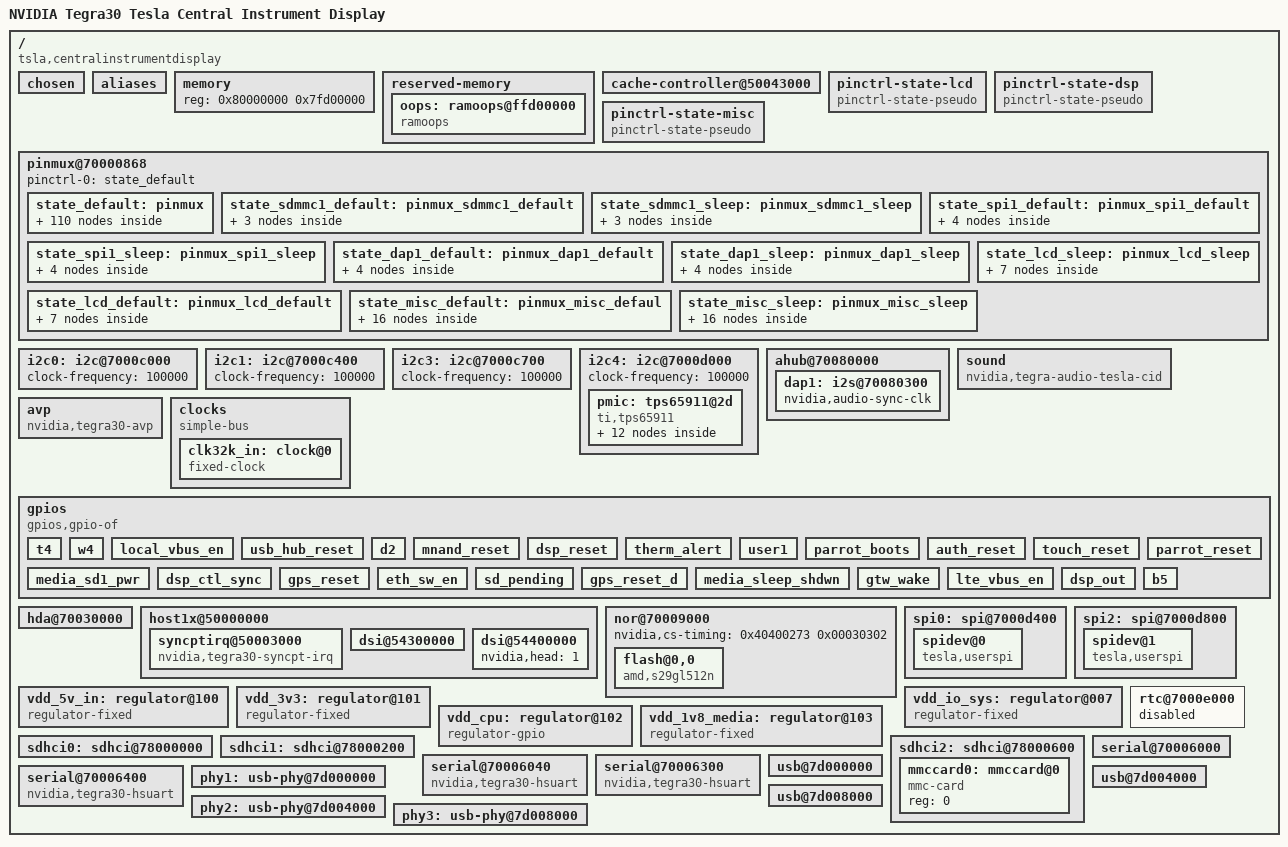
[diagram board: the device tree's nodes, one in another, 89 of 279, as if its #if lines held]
/dts-v1/;

#include "tegra30.dtsi"
#include "tegra30-platformdevice-compat.dtsi"

/ {
	model = "NVIDIA Tegra30 Tesla Central Instrument Display";
	compatible = "tsla,centralinstrumentdisplay", "nvidia,tegra30";

	chosen {
		/* for initial, just boot to a ram disc */
		bootargs = "console=ttyS0,115200n8 earlyprintk root=/dev/ram0";
	};

	aliases {
		serial0 = &uarta;
		serial1 = &uartb;
		serial2 = &uartc;
		serial3 = &uartd;
		serial4 = &uarte;
		i2c0 = &i2c0;
		i2c1 = &i2c1;
		i2c3 = &i2c3;
		i2c4 = &i2c4;
		spi0 = &spi0;
		spi2 = &spi2;
		mmc0 = &sdhci2;
		mmc1 = &sdhci0;
		mmc2 = &sdhci1;
		mmcblock0 = &mmccard0;
	};

	memory {
		/*
		 * Note, last 1 MiB is either reserved or unusable, and
		 * the 2 MiB below that is reserved for ramoops pstore.
		 */
		reg = <0x80000000 0x7fd00000>;
	};

	reserved-memory {
		#size-cells = <1>;
		#address-cells = <1>;
		ranges;

		oops: ramoops@ffd00000 {
			compatible = "ramoops";
			reg = <0xffd00000 0x200000>;
			record-size = <0x20000>;	/* 128KiB for oops */
			console-size = <0x2000>;	/* 8KiB */
			pmsg-size = <0x2000>;
			no-dump-oops;
			no-map;
		};
	};

	/* updated pl310 settings */
	cache-controller@50043000 {
		prefetch-data = <1>;
		prefetch-instr = <1>;
		arm,filter-ranges = < 0x80000000 0x7ff00000 >;
	};

	pinctrl-state-lcd {
		compatible = "pinctrl-state-pseudo";

		pinctrl-names = "default", "sleep";
		pinctrl-0 = <&state_lcd_default>;
		pinctrl-1 = <&state_lcd_sleep>;
	};

	pinctrl-state-dsp {
		compatible = "pinctrl-state-pseudo";

		pinctrl-names = "default", "sleep";
		pinctrl-0 = <&state_dap1_default &state_spi1_default>;
		pinctrl-1 = <&state_dap1_sleep &state_spi1_sleep>;
	};

	pinctrl-state-misc {
		compatible = "pinctrl-state-pseudo";

		pinctrl-names = "default", "sleep";
		pinctrl-0 = <&state_misc_default>;
		pinctrl-1 = <&state_misc_sleep>;
	};

	pinmux@70000868 {
		pinctrl-names = "default";
		pinctrl-0 = <&state_default>;

		state_default: pinmux {

			/* Pad Control Groups */
			ao1 {
				nvidia,pins = "drive_ao1";
				nvidia,high-speed-mode = <TEGRA_PIN_DISABLE>;
				nvidia,schmitt = <TEGRA_PIN_ENABLE>;
				nvidia,low-power-mode = <TEGRA_PIN_LP_DRIVE_DIV_1>;
				nvidia,pull-down-strength = <31>;
				nvidia,pull-up-strength = <31>;
				nvidia,slew-rate-rising = <TEGRA_PIN_SLEW_RATE_FASTEST>;
				nvidia,slew-rate-falling = <TEGRA_PIN_SLEW_RATE_FASTEST>;
			};
			at1 {
				nvidia,pins = "drive_at1";
				nvidia,high-speed-mode = <TEGRA_PIN_ENABLE>;
				nvidia,schmitt = <TEGRA_PIN_ENABLE>;
				nvidia,low-power-mode = <TEGRA_PIN_LP_DRIVE_DIV_8>;
				nvidia,pull-down-strength = <0>;
				nvidia,pull-up-strength = <0>;
				nvidia,slew-rate-rising = <TEGRA_PIN_SLEW_RATE_SLOWEST>;
				nvidia,slew-rate-falling = <TEGRA_PIN_SLEW_RATE_SLOWEST>;
			};
			at2 {
				nvidia,pins = "drive_at2";
				nvidia,high-speed-mode = <TEGRA_PIN_ENABLE>;
				nvidia,schmitt = <TEGRA_PIN_ENABLE>;
				nvidia,low-power-mode = <TEGRA_PIN_LP_DRIVE_DIV_8>;
				nvidia,pull-down-strength = <0>;
				nvidia,pull-up-strength = <0>;
				nvidia,slew-rate-rising = <TEGRA_PIN_SLEW_RATE_SLOWEST>;
				nvidia,slew-rate-falling = <TEGRA_PIN_SLEW_RATE_SLOWEST>;
			};
			at3 {
				nvidia,pins = "drive_at3";
				nvidia,high-speed-mode = <TEGRA_PIN_ENABLE>;
				nvidia,schmitt = <TEGRA_PIN_ENABLE>;
				nvidia,low-power-mode = <TEGRA_PIN_LP_DRIVE_DIV_8>;
				nvidia,pull-down-strength = <0>;
				nvidia,pull-up-strength = <0>;
				nvidia,slew-rate-rising = <TEGRA_PIN_SLEW_RATE_SLOWEST>;
				nvidia,slew-rate-falling = <TEGRA_PIN_SLEW_RATE_SLOWEST>;
			};
			at4 {
				nvidia,pins = "drive_at4";
				nvidia,high-speed-mode = <TEGRA_PIN_DISABLE>;
				nvidia,schmitt = <TEGRA_PIN_DISABLE>;
				nvidia,low-power-mode = <TEGRA_PIN_LP_DRIVE_DIV_1>;
				nvidia,pull-down-strength = <0>;
				nvidia,pull-up-strength = <0>;
				nvidia,slew-rate-rising = <TEGRA_PIN_SLEW_RATE_SLOWEST>;
				nvidia,slew-rate-falling = <TEGRA_PIN_SLEW_RATE_SLOWEST>;
			};
			at5 {
				nvidia,pins = "drive_at5";
				nvidia,high-speed-mode = <TEGRA_PIN_DISABLE>;
				nvidia,schmitt = <TEGRA_PIN_ENABLE>;
				nvidia,low-power-mode = <TEGRA_PIN_LP_DRIVE_DIV_1>;
				nvidia,pull-down-strength = <12>;
				nvidia,pull-up-strength = <30>;
				nvidia,slew-rate-rising = <TEGRA_PIN_SLEW_RATE_FASTEST>;
				nvidia,slew-rate-falling = <TEGRA_PIN_SLEW_RATE_FASTEST>;
			};
			dap1 {
				nvidia,pins = "drive_dap1";
				nvidia,high-speed-mode = <TEGRA_PIN_DISABLE>;
				nvidia,schmitt = <TEGRA_PIN_DISABLE>;
				nvidia,low-power-mode = <TEGRA_PIN_LP_DRIVE_DIV_1>;
				nvidia,pull-down-strength = <31>;
				nvidia,pull-up-strength = <31>;
				nvidia,slew-rate-rising = <TEGRA_PIN_SLEW_RATE_SLOWEST>;
				nvidia,slew-rate-falling = <TEGRA_PIN_SLEW_RATE_SLOWEST>;
			};
			dap2 {
				nvidia,pins = "drive_dap2";
				nvidia,high-speed-mode = <TEGRA_PIN_ENABLE>;
				nvidia,schmitt = <TEGRA_PIN_ENABLE>;
				nvidia,low-power-mode = <TEGRA_PIN_LP_DRIVE_DIV_8>;
				nvidia,pull-down-strength = <0>;
				nvidia,pull-up-strength = <0>;
				nvidia,slew-rate-rising = <TEGRA_PIN_SLEW_RATE_SLOWEST>;
				nvidia,slew-rate-falling = <TEGRA_PIN_SLEW_RATE_SLOWEST>;
			};
			dap3 {
				nvidia,pins = "drive_dap3";
				nvidia,high-speed-mode = <TEGRA_PIN_DISABLE>;
				nvidia,schmitt = <TEGRA_PIN_DISABLE>;
				nvidia,low-power-mode = <TEGRA_PIN_LP_DRIVE_DIV_1>;
				nvidia,pull-down-strength = <31>;
				nvidia,pull-up-strength = <31>;
				nvidia,slew-rate-rising = <TEGRA_PIN_SLEW_RATE_SLOWEST>;
				nvidia,slew-rate-falling = <TEGRA_PIN_SLEW_RATE_SLOWEST>;
			};
			dap4 {
				nvidia,pins = "drive_dap4";
				nvidia,high-speed-mode = <TEGRA_PIN_ENABLE>;
				nvidia,schmitt = <TEGRA_PIN_ENABLE>;
				nvidia,low-power-mode = <TEGRA_PIN_LP_DRIVE_DIV_8>;
				nvidia,pull-down-strength = <0>;
				nvidia,pull-up-strength = <0>;
				nvidia,slew-rate-rising = <TEGRA_PIN_SLEW_RATE_SLOWEST>;
				nvidia,slew-rate-falling = <TEGRA_PIN_SLEW_RATE_SLOWEST>;
			};
			dbg {
				nvidia,pins = "drive_dbg";
				nvidia,high-speed-mode = <TEGRA_PIN_ENABLE>;
				nvidia,schmitt = <TEGRA_PIN_ENABLE>;
				nvidia,low-power-mode = <TEGRA_PIN_LP_DRIVE_DIV_2>;
				nvidia,pull-down-strength = <20>;
				nvidia,pull-up-strength = <0>;
				nvidia,slew-rate-rising = <TEGRA_PIN_SLEW_RATE_SLOWEST>;
				nvidia,slew-rate-falling = <TEGRA_PIN_SLEW_RATE_SLOWEST>;
			};
			ddc {
				nvidia,pins = "drive_ddc";
				nvidia,high-speed-mode = <TEGRA_PIN_DISABLE>;
				nvidia,schmitt = <TEGRA_PIN_ENABLE>;
				nvidia,low-power-mode = <TEGRA_PIN_LP_DRIVE_DIV_1>;
				nvidia,pull-down-strength = <31>;
				nvidia,pull-up-strength = <31>;
				nvidia,slew-rate-rising = <TEGRA_PIN_SLEW_RATE_FASTEST>;
				nvidia,slew-rate-falling = <TEGRA_PIN_SLEW_RATE_FASTEST>;
			};
			gme {
				nvidia,pins = "drive_gme";
				nvidia,high-speed-mode = <TEGRA_PIN_DISABLE>;
				nvidia,schmitt = <TEGRA_PIN_ENABLE>;
				nvidia,low-power-mode = <TEGRA_PIN_LP_DRIVE_DIV_1>;
				nvidia,pull-down-strength = <1>;
				nvidia,pull-up-strength = <4>;
				nvidia,slew-rate-rising = <TEGRA_PIN_SLEW_RATE_SLOWEST>;
				nvidia,slew-rate-falling = <TEGRA_PIN_SLEW_RATE_SLOWEST>;
			};
			gmf {
				nvidia,pins = "drive_gmf";
				nvidia,high-speed-mode = <TEGRA_PIN_DISABLE>;
				nvidia,schmitt = <TEGRA_PIN_ENABLE>;
				nvidia,low-power-mode = <TEGRA_PIN_LP_DRIVE_DIV_1>;
				nvidia,pull-down-strength = <0>;
				nvidia,pull-up-strength = <0>;
				nvidia,slew-rate-rising = <TEGRA_PIN_SLEW_RATE_SLOWEST>;
				nvidia,slew-rate-falling = <TEGRA_PIN_SLEW_RATE_SLOWEST>;
			};
			gmg {
				nvidia,pins = "drive_gmg";
				nvidia,high-speed-mode = <TEGRA_PIN_DISABLE>;
				nvidia,schmitt = <TEGRA_PIN_ENABLE>;
				nvidia,low-power-mode = <TEGRA_PIN_LP_DRIVE_DIV_1>;
				nvidia,pull-down-strength = <3>;
				nvidia,pull-up-strength = <0>;
				nvidia,slew-rate-rising = <TEGRA_PIN_SLEW_RATE_SLOWEST>;
				nvidia,slew-rate-falling = <TEGRA_PIN_SLEW_RATE_SLOWEST>;
			};
			gmh {
				nvidia,pins = "drive_gmh";
				nvidia,high-speed-mode = <TEGRA_PIN_DISABLE>;
				nvidia,schmitt = <TEGRA_PIN_ENABLE>;
				nvidia,low-power-mode = <TEGRA_PIN_LP_DRIVE_DIV_1>;
				nvidia,pull-down-strength = <0>;
				nvidia,pull-up-strength = <12>;
				nvidia,slew-rate-rising = <TEGRA_PIN_SLEW_RATE_SLOWEST>;
				nvidia,slew-rate-falling = <TEGRA_PIN_SLEW_RATE_SLOWEST>;
			};
			lcd1 {
				nvidia,pins = "drive_lcd1";
				nvidia,high-speed-mode = <TEGRA_PIN_DISABLE>;
				nvidia,schmitt = <TEGRA_PIN_ENABLE>;
				nvidia,low-power-mode = <TEGRA_PIN_LP_DRIVE_DIV_1>;
				nvidia,pull-down-strength = <31>;
				nvidia,pull-up-strength = <31>;
				nvidia,slew-rate-rising = <TEGRA_PIN_SLEW_RATE_FASTEST>;
				nvidia,slew-rate-falling = <TEGRA_PIN_SLEW_RATE_FASTEST>;
			};
			lcd2 {
				nvidia,pins = "drive_lcd2";
				nvidia,high-speed-mode = <TEGRA_PIN_DISABLE>;
				nvidia,schmitt = <TEGRA_PIN_ENABLE>;
				nvidia,low-power-mode = <TEGRA_PIN_LP_DRIVE_DIV_1>;
				nvidia,pull-down-strength = <6>;
				nvidia,pull-up-strength = <6>;
				nvidia,slew-rate-rising = <TEGRA_PIN_SLEW_RATE_FASTEST>;
				nvidia,slew-rate-falling = <TEGRA_PIN_SLEW_RATE_FASTEST>;
			};
			spi {
				nvidia,pins = "drive_spi";
				nvidia,high-speed-mode = <TEGRA_PIN_ENABLE>;
				nvidia,schmitt = <TEGRA_PIN_ENABLE>;
				nvidia,low-power-mode = <TEGRA_PIN_LP_DRIVE_DIV_8>;
				nvidia,pull-down-strength = <0>;
				nvidia,pull-up-strength = <0>;
				nvidia,slew-rate-rising = <TEGRA_PIN_SLEW_RATE_SLOWEST>;
				nvidia,slew-rate-falling = <TEGRA_PIN_SLEW_RATE_SLOWEST>;
			};
			uaa {
				nvidia,pins = "drive_uaa";
				nvidia,high-speed-mode = <TEGRA_PIN_DISABLE>;
				nvidia,schmitt = <TEGRA_PIN_DISABLE>;
				nvidia,low-power-mode = <TEGRA_PIN_LP_DRIVE_DIV_1>;
				nvidia,pull-down-strength = <0>;
				nvidia,pull-up-strength = <0>;
				nvidia,slew-rate-rising = <TEGRA_PIN_SLEW_RATE_SLOWEST>;
				nvidia,slew-rate-falling = <TEGRA_PIN_SLEW_RATE_SLOWEST>;
			};
			uab {
				nvidia,pins = "drive_uab";
				nvidia,high-speed-mode = <TEGRA_PIN_DISABLE>;
				nvidia,schmitt = <TEGRA_PIN_ENABLE>;
				nvidia,low-power-mode = <TEGRA_PIN_LP_DRIVE_DIV_1>;
				nvidia,pull-down-strength = <4>;
				nvidia,pull-up-strength = <1>;
				nvidia,slew-rate-rising = <TEGRA_PIN_SLEW_RATE_SLOWEST>;
				nvidia,slew-rate-falling = <TEGRA_PIN_SLEW_RATE_SLOWEST>;
			};
			uda {
				nvidia,pins = "drive_uda";
				nvidia,high-speed-mode = <TEGRA_PIN_DISABLE>;
				nvidia,schmitt = <TEGRA_PIN_ENABLE>;
				nvidia,low-power-mode = <TEGRA_PIN_LP_DRIVE_DIV_1>;
				nvidia,pull-down-strength = <4>;
				nvidia,pull-up-strength = <1>;
				nvidia,slew-rate-rising = <TEGRA_PIN_SLEW_RATE_SLOWEST>;
				nvidia,slew-rate-falling = <TEGRA_PIN_SLEW_RATE_SLOWEST>;
			};
			uart2 {
				nvidia,pins = "drive_uart2";
				nvidia,high-speed-mode = <TEGRA_PIN_ENABLE>;
				nvidia,schmitt = <TEGRA_PIN_ENABLE>;
				nvidia,low-power-mode = <TEGRA_PIN_LP_DRIVE_DIV_8>;
				nvidia,pull-down-strength = <0>;
				nvidia,pull-up-strength = <0>;
				nvidia,slew-rate-rising = <TEGRA_PIN_SLEW_RATE_SLOWEST>;
				nvidia,slew-rate-falling = <TEGRA_PIN_SLEW_RATE_SLOWEST>;
			};
			uart3 {
				nvidia,pins = "drive_uart3";
				nvidia,high-speed-mode = <TEGRA_PIN_ENABLE>;
				nvidia,schmitt = <TEGRA_PIN_ENABLE>;
				nvidia,low-power-mode = <TEGRA_PIN_LP_DRIVE_DIV_8>;
				nvidia,pull-down-strength = <0>;
				nvidia,pull-up-strength = <0>;
				nvidia,slew-rate-rising = <TEGRA_PIN_SLEW_RATE_SLOWEST>;
				nvidia,slew-rate-falling = <TEGRA_PIN_SLEW_RATE_SLOWEST>;
			};
			sdio1 {
				nvidia,pins = "drive_sdio1";
				nvidia,high-speed-mode = <TEGRA_PIN_DISABLE>;
				nvidia,schmitt = <TEGRA_PIN_DISABLE>;
				nvidia,pull-down-strength = <29>;
				nvidia,pull-up-strength = <22>;
				nvidia,slew-rate-rising = <TEGRA_PIN_SLEW_RATE_SLOWEST>;
				nvidia,slew-rate-falling = <TEGRA_PIN_SLEW_RATE_SLOWEST>;
			};
			sdio3 {
				nvidia,pins = "drive_sdio3";
				nvidia,high-speed-mode = <TEGRA_PIN_DISABLE>;
				nvidia,schmitt = <TEGRA_PIN_ENABLE>;
				nvidia,pull-down-strength = <4>;
				nvidia,pull-up-strength = <1>;
				nvidia,slew-rate-rising = <TEGRA_PIN_SLEW_RATE_FASTEST>;
				nvidia,slew-rate-falling = <TEGRA_PIN_SLEW_RATE_FASTEST>;
			};

			/* CRT pinmux */
			crt_hsync_pv6 {
				nvidia,pins = "crt_hsync_pv6";
				nvidia,function = "crt";
				nvidia,pull = <TEGRA_PIN_PULL_NONE>;
				nvidia,tristate = <TEGRA_PIN_DISABLE>;
				nvidia,enable-input = <TEGRA_PIN_ENABLE>;
			};

			crt_vsync_pv7 {
				nvidia,pins = "crt_vsync_pv7";
				nvidia,function = "rsvd2";
				nvidia,pull = <TEGRA_PIN_PULL_NONE>;
				nvidia,tristate = <TEGRA_PIN_DISABLE>;
				nvidia,enable-input = <TEGRA_PIN_ENABLE>;
			};


			/* SDMMC2 pinmux */
			kb_row10_ps2 {
				nvidia,pins = "kb_row10_ps2";
				nvidia,function = "sdmmc2";
				nvidia,pull = <TEGRA_PIN_PULL_NONE>;
				nvidia,tristate = <TEGRA_PIN_DISABLE>;
				nvidia,enable-input = <TEGRA_PIN_ENABLE>;
			};
			kb_rows {
				nvidia,pins = "kb_row11_ps3",
						"kb_row12_ps4",
						"kb_row13_ps5",
						"kb_row14_ps6",
						"kb_row15_ps7",
						"kb_row6_pr6",
						"kb_row7_pr7",
						"kb_row8_ps0",
						"kb_row9_ps1";
				nvidia,function = "sdmmc2";
				nvidia,pull = <TEGRA_PIN_PULL_UP>;
				nvidia,tristate = <TEGRA_PIN_DISABLE>;
				nvidia,enable-input = <TEGRA_PIN_ENABLE>;
			};

			/* SDMMC3 pinmux*/
			sdmmc3_cmd_pa7 {
				nvidia,pins = "sdmmc3_cmd_pa7";
				nvidia,function = "sdmmc3";
				nvidia,pull = <TEGRA_PIN_PULL_NONE>;
				nvidia,tristate = <TEGRA_PIN_DISABLE>;
				nvidia,enable-input = <TEGRA_PIN_ENABLE>;
			};

			sdmmc3_dat3_pb4 {
				nvidia,pins = "sdmmc3_dat3_pb4";
				nvidia,function = "rsvd1";
				nvidia,pull = <TEGRA_PIN_PULL_NONE>;
				nvidia,tristate = <TEGRA_PIN_DISABLE>;
				nvidia,enable-input = <TEGRA_PIN_ENABLE>;
			};

			sdmmc3_dat7_pd4 {
				nvidia,pins = "sdmmc3_dat7_pd4";
				nvidia,function = "sdmmc3";
				nvidia,pull = <TEGRA_PIN_PULL_NONE>;
				nvidia,tristate = <TEGRA_PIN_DISABLE>;
				nvidia,enable-input = <TEGRA_PIN_ENABLE>;
			};


			/* SDMMC4 pinmux */
			cam_i2c_scl_pbb1 {
				nvidia,pins = "cam_i2c_scl_pbb1";
				nvidia,function = "sdmmc4";
				nvidia,pull = <TEGRA_PIN_PULL_UP>;
				nvidia,tristate = <TEGRA_PIN_DISABLE>;
				nvidia,enable-input = <TEGRA_PIN_ENABLE>;
				nvidia,open-drain = <TEGRA_PIN_DISABLE>;
				nvidia,io-reset = <TEGRA_PIN_DISABLE>;
			};
			cam_i2c_sda_pbb2 {
				nvidia,pins = "cam_i2c_sda_pbb2";
				nvidia,function = "sdmmc4";
				nvidia,pull = <TEGRA_PIN_PULL_UP>;
				nvidia,tristate = <TEGRA_PIN_DISABLE>;
				nvidia,enable-input = <TEGRA_PIN_ENABLE>;
				nvidia,open-drain = <TEGRA_PIN_DISABLE>;
				nvidia,io-reset = <TEGRA_PIN_DISABLE>;
			};
			cam_mclk_pcc0 {
				nvidia,pins = "cam_mclk_pcc0";
				nvidia,function = "sdmmc4";
				nvidia,pull = <TEGRA_PIN_PULL_NONE>;
				nvidia,tristate = <TEGRA_PIN_DISABLE>;
				nvidia,enable-input = <TEGRA_PIN_ENABLE>;
			};
			pcc1 {
				nvidia,pins = "pcc1";
				nvidia,function = "sdmmc4";
				nvidia,pull = <TEGRA_PIN_PULL_NONE>;
				nvidia,tristate = <TEGRA_PIN_DISABLE>;
				nvidia,enable-input = <TEGRA_PIN_ENABLE>;
			};
			pcc2 {
				nvidia,pins = "pcc2";
				nvidia,function = "rsvd4";
				nvidia,pull = <TEGRA_PIN_PULL_UP>;
				nvidia,tristate = <TEGRA_PIN_DISABLE>;
				nvidia,enable-input = <TEGRA_PIN_ENABLE>;
			};
			pbb0 {
				nvidia,pins = "pbb0";
				nvidia,function = "sdmmc4";
				nvidia,pull = <TEGRA_PIN_PULL_UP>;
				nvidia,tristate = <TEGRA_PIN_DISABLE>;
				nvidia,enable-input = <TEGRA_PIN_ENABLE>;
			};
			pbb3 {
				nvidia,pins = "pbb3";
				nvidia,function = "sdmmc4";
				nvidia,pull = <TEGRA_PIN_PULL_UP>;
				nvidia,tristate = <TEGRA_PIN_DISABLE>;
				nvidia,enable-input = <TEGRA_PIN_ENABLE>;
			};
			pbb4 {
				nvidia,pins = "pbb4";
				nvidia,function = "sdmmc4";
				nvidia,pull = <TEGRA_PIN_PULL_UP>;
				nvidia,tristate = <TEGRA_PIN_DISABLE>;
				nvidia,enable-input = <TEGRA_PIN_ENABLE>;
			};
			pbb5 {
				nvidia,pins = "pbb5";
				nvidia,function = "sdmmc4";
				nvidia,pull = <TEGRA_PIN_PULL_UP>;
				nvidia,tristate = <TEGRA_PIN_DISABLE>;
				nvidia,enable-input = <TEGRA_PIN_ENABLE>;
			};
			pbb6 {
				nvidia,pins = "pbb6";
				nvidia,function = "sdmmc4";
				nvidia,pull = <TEGRA_PIN_PULL_UP>;
				nvidia,tristate = <TEGRA_PIN_DISABLE>;
				nvidia,enable-input = <TEGRA_PIN_ENABLE>;
			};
			pbb7 {
				nvidia,pins = "pbb7";
				nvidia,function = "sdmmc4";
				nvidia,pull = <TEGRA_PIN_PULL_UP>;
				nvidia,tristate = <TEGRA_PIN_DISABLE>;
				nvidia,enable-input = <TEGRA_PIN_ENABLE>;
			};

			/* UART1 pinmux */
			ulpi_data0_po1 {
				nvidia,pins = "ulpi_data0_po1";
				nvidia,function = "uarta";
				nvidia,pull = <TEGRA_PIN_PULL_NONE>;
				nvidia,tristate = <TEGRA_PIN_DISABLE>;
				nvidia,enable-input = <TEGRA_PIN_DISABLE>;
			};
			/* I2C1 pinmux */
			gen1_i2c_scl_pc4 {
				nvidia,pins = "gen1_i2c_scl_pc4";
				nvidia,function = "i2c1";
				nvidia,pull = <TEGRA_PIN_PULL_NONE>;
				nvidia,tristate = <TEGRA_PIN_DISABLE>;
				nvidia,enable-input = <TEGRA_PIN_ENABLE>;
				nvidia,lock = <TEGRA_PIN_DISABLE>;
				nvidia,open-drain = <TEGRA_PIN_ENABLE>;
			};
			gen1_i2c_sda_pc5 {
				nvidia,pins = "gen1_i2c_sda_pc5";
				nvidia,function = "i2c1";
				nvidia,pull = <TEGRA_PIN_PULL_NONE>;
				nvidia,tristate = <TEGRA_PIN_DISABLE>;
				nvidia,enable-input = <TEGRA_PIN_ENABLE>;
				nvidia,lock = <TEGRA_PIN_DISABLE>;
				nvidia,open-drain = <TEGRA_PIN_ENABLE>;
			};

			/* I2C2 pinmux */
			gen2_i2c_scl_pt5 {
				nvidia,pins = "gen2_i2c_scl_pt5";
				nvidia,function = "i2c2";
				nvidia,pull = <TEGRA_PIN_PULL_NONE>;
				nvidia,tristate = <TEGRA_PIN_DISABLE>;
				nvidia,enable-input = <TEGRA_PIN_ENABLE>;
				nvidia,lock = <TEGRA_PIN_DISABLE>;
				nvidia,open-drain = <TEGRA_PIN_ENABLE>;
			};
			gen2_i2c_sda_pt6 {
				nvidia,pins = "gen2_i2c_sda_pt6";
				nvidia,function = "i2c2";
				nvidia,pull = <TEGRA_PIN_PULL_NONE>;
				nvidia,tristate = <TEGRA_PIN_DISABLE>;
				nvidia,enable-input = <TEGRA_PIN_ENABLE>;
				nvidia,lock = <TEGRA_PIN_DISABLE>;
				nvidia,open-drain = <TEGRA_PIN_ENABLE>;
			};

			/* I2C4 pinmux */
			ddc_scl_pv4 {
				nvidia,pins = "ddc_scl_pv4";
				nvidia,function = "i2c4";
				nvidia,pull = <TEGRA_PIN_PULL_NONE>;
				nvidia,tristate = <TEGRA_PIN_DISABLE>;
				nvidia,lock = <TEGRA_PIN_DISABLE>;
				nvidia,enable-input = <TEGRA_PIN_ENABLE>;
			};
			ddc_sda_pv5 {
				nvidia,pins = "ddc_sda_pv5";
				nvidia,function = "i2c4";
				nvidia,pull = <TEGRA_PIN_PULL_NONE>;
				nvidia,tristate = <TEGRA_PIN_DISABLE>;
				nvidia,lock = <TEGRA_PIN_DISABLE>;
				nvidia,enable-input = <TEGRA_PIN_ENABLE>;
			};

			/* PWRI2C pinmux */
			pwr_i2c_scl_pz6 {
				nvidia,pins = "pwr_i2c_scl_pz6";
				nvidia,function = "i2cpwr";
				nvidia,pull = <TEGRA_PIN_PULL_NONE>;
				nvidia,tristate = <TEGRA_PIN_DISABLE>;
				nvidia,enable-input = <TEGRA_PIN_ENABLE>;
				nvidia,open-drain = <TEGRA_PIN_ENABLE>;
			};
			pwr_i2c_sda_pz7 {
				nvidia,pins = "pwr_i2c_sda_pz7";
				nvidia,function = "i2cpwr";
				nvidia,pull = <TEGRA_PIN_PULL_NONE>;
				nvidia,tristate = <TEGRA_PIN_DISABLE>;
				nvidia,enable-input = <TEGRA_PIN_ENABLE>;
				nvidia,open-drain = <TEGRA_PIN_ENABLE>;
			};


			/* SPI2 pinmux*/
			spi1_cs0_n_px6 {
				nvidia,pins = "spi1_cs0_n_px6";
				nvidia,function = "spi2";
				nvidia,pull = <TEGRA_PIN_PULL_NONE>;
				nvidia,tristate = <TEGRA_PIN_DISABLE>;
				nvidia,enable-input = <TEGRA_PIN_ENABLE>;
			};
			spi1_sck_px5 {
				nvidia,pins = "spi1_sck_px5";
				nvidia,function = "spi2";
				nvidia,pull = <TEGRA_PIN_PULL_NONE>;
				nvidia,tristate = <TEGRA_PIN_DISABLE>;
				nvidia,enable-input = <TEGRA_PIN_ENABLE>;
			};
			spi2_cs1_n_pw2 {
				nvidia,pins = "spi2_cs1_n_pw2";
				nvidia,function = "spi2";
				nvidia,pull = <TEGRA_PIN_PULL_NONE>;
				nvidia,tristate = <TEGRA_PIN_ENABLE>;
				nvidia,enable-input = <TEGRA_PIN_ENABLE>;
			};
			spi2_cs2_n_pw3 {
				nvidia,pins = "spi2_cs2_n_pw3";
				nvidia,function = "spi2";
				nvidia,pull = <TEGRA_PIN_PULL_NONE>;
				nvidia,tristate = <TEGRA_PIN_DISABLE>;
				nvidia,enable-input = <TEGRA_PIN_ENABLE>;
			};
			ulpi_data4_po5 {
				nvidia,pins = "ulpi_data4_po5";
				nvidia,function = "spi2";
				nvidia,pull = <TEGRA_PIN_PULL_NONE>;
				nvidia,tristate = <TEGRA_PIN_DISABLE>;
				nvidia,enable-input = <TEGRA_PIN_ENABLE>;
			};
			ulpi_data5_po6 {
				nvidia,pins = "ulpi_data5_po6";
				nvidia,function = "spi2";
				nvidia,pull = <TEGRA_PIN_PULL_NONE>;
				nvidia,tristate = <TEGRA_PIN_DISABLE>;
				nvidia,enable-input = <TEGRA_PIN_ENABLE>;
			};
			ulpi_data6_po7 {
				nvidia,pins = "ulpi_data6_po7";
				nvidia,function = "spi2";
				nvidia,pull = <TEGRA_PIN_PULL_NONE>;
				nvidia,tristate = <TEGRA_PIN_DISABLE>;
				nvidia,enable-input = <TEGRA_PIN_ENABLE>;
			};
			ulpi_data7_po0 {
				nvidia,pins = "ulpi_data7_po0";
				nvidia,function = "spi2";
				nvidia,pull = <TEGRA_PIN_PULL_NONE>;
				nvidia,tristate = <TEGRA_PIN_DISABLE>;
				nvidia,enable-input = <TEGRA_PIN_ENABLE>;
			};

			/* SPDIF pinmux */
			spdif_in_pk6 {
				nvidia,pins = "spdif_in_pk6";
				nvidia,function = "spdif";
				nvidia,pull = <TEGRA_PIN_PULL_NONE>;
				nvidia,tristate = <TEGRA_PIN_ENABLE>;
				nvidia,enable-input = <TEGRA_PIN_ENABLE>;
			};

			/* DAP2 pinmux */
			dap3_fs_pp0 {
				nvidia,pins = "dap3_fs_pp0";
				nvidia,function = "i2s2";
				nvidia,pull = <TEGRA_PIN_PULL_NONE>;
				nvidia,tristate = <TEGRA_PIN_ENABLE>;
				nvidia,enable-input = <TEGRA_PIN_ENABLE>;
			};
			dap3_din_pp1 {
				nvidia,pins = "dap3_din_pp1";
				nvidia,function = "i2s2";
				nvidia,pull = <TEGRA_PIN_PULL_NONE>;
				nvidia,tristate = <TEGRA_PIN_ENABLE>;
				nvidia,enable-input = <TEGRA_PIN_ENABLE>;
			};
			dap3_dout_pp2 {
				nvidia,pins = "dap3_dout_pp2";
				nvidia,function = "i2s2";
				nvidia,pull = <TEGRA_PIN_PULL_NONE>;
				nvidia,tristate = <TEGRA_PIN_ENABLE>;
				nvidia,enable-input = <TEGRA_PIN_ENABLE>;
			};
			dap3_sclk_pp3 {
				nvidia,pins = "dap3_sclk_pp3";
				nvidia,function = "i2s2";
				nvidia,pull = <TEGRA_PIN_PULL_NONE>;
				nvidia,tristate = <TEGRA_PIN_ENABLE>;
				nvidia,enable-input = <TEGRA_PIN_ENABLE>;
			};

			/* DAP3 pinmux */
			sdmmc4_dat4_paa4 {
				nvidia,pins = "sdmmc4_dat4_paa4";
				nvidia,function = "i2s4";
				nvidia,pull = <TEGRA_PIN_PULL_NONE>;
				nvidia,tristate = <TEGRA_PIN_DISABLE>;
				nvidia,enable-input = <TEGRA_PIN_ENABLE>;
				nvidia,lock = <TEGRA_PIN_DISABLE>;
				nvidia,io-reset = <TEGRA_PIN_DISABLE>;
			};
			sdmmc4_dat5_paa5 {
				nvidia,pins = "sdmmc4_dat5_paa5";
				nvidia,function = "i2s4";
				nvidia,pull = <TEGRA_PIN_PULL_NONE>;
				nvidia,tristate = <TEGRA_PIN_DISABLE>;
				nvidia,enable-input = <TEGRA_PIN_ENABLE>;
				nvidia,lock = <TEGRA_PIN_DISABLE>;
				nvidia,io-reset = <TEGRA_PIN_DISABLE>;
			};
			sdmmc4_dat6_paa6 {
				nvidia,pins = "sdmmc4_dat6_paa6";
				nvidia,function = "i2s4";
				nvidia,pull = <TEGRA_PIN_PULL_NONE>;
				nvidia,tristate = <TEGRA_PIN_DISABLE>;
				nvidia,enable-input = <TEGRA_PIN_ENABLE>;
				nvidia,lock = <TEGRA_PIN_DISABLE>;
				nvidia,io-reset = <TEGRA_PIN_DISABLE>;
			};
			sdmmc4_dat7_paa7 {
				nvidia,pins = "sdmmc4_dat7_paa7";
				nvidia,function = "i2s4";
				nvidia,pull = <TEGRA_PIN_PULL_NONE>;
				nvidia,tristate = <TEGRA_PIN_DISABLE>;
				nvidia,enable-input = <TEGRA_PIN_ENABLE>;
				nvidia,lock = <TEGRA_PIN_DISABLE>;
				nvidia,io-reset = <TEGRA_PIN_DISABLE>;
			};

			/* NOR pinmux */
			gmi_input {
				nvidia,pins = "gmi_ad0_pg0",
						"gmi_ad1_pg1",
						"gmi_ad2_pg2",
						"gmi_ad3_pg3",
						"gmi_ad4_pg4",
						"gmi_ad5_pg5",
						"gmi_ad6_pg6",
						"gmi_ad7_pg7",
						"gmi_ad8_ph0",
						"gmi_ad9_ph1",
						"gmi_ad10_ph2",
						"gmi_ad11_ph3",
						"gmi_ad12_ph4",
						"gmi_ad13_ph5",
						"gmi_ad14_ph6",
						"gmi_ad15_ph7",
                        "gmi_wait_pi7";
				nvidia,function = "gmi";
				nvidia,pull = <TEGRA_PIN_PULL_NONE>;
				nvidia,tristate = <TEGRA_PIN_DISABLE>;
				nvidia,enable-input = <TEGRA_PIN_ENABLE>;
			};
			gmi_adv_n_pk0 {
				nvidia,pins = "gmi_adv_n_pk0";
				nvidia,function = "nand";
				nvidia,pull = <TEGRA_PIN_PULL_NONE>;
				nvidia,tristate = <TEGRA_PIN_DISABLE>;
				nvidia,enable-input = <TEGRA_PIN_DISABLE>;
			};
			gmi_clk_pk1 {
				nvidia,pins = "gmi_clk_pk1";
				nvidia,function = "nand";
				nvidia,pull = <TEGRA_PIN_PULL_NONE>;
				nvidia,tristate = <TEGRA_PIN_DISABLE>;
				nvidia,enable-input = <TEGRA_PIN_DISABLE>;
			};
			gmi_cs0_n_pj0 {
				nvidia,pins = "gmi_cs0_n_pj0";
				nvidia,function = "gmi";
				nvidia,pull = <TEGRA_PIN_PULL_NONE>;
				nvidia,tristate = <TEGRA_PIN_DISABLE>;
				nvidia,enable-input = <TEGRA_PIN_DISABLE>;
			};
			gmi_oe_n_pi1 {
				nvidia,pins = "gmi_oe_n_pi1";
				nvidia,function = "gmi";
				nvidia,pull = <TEGRA_PIN_PULL_NONE>;
				nvidia,tristate = <TEGRA_PIN_DISABLE>;
				nvidia,enable-input = <TEGRA_PIN_DISABLE>;
			};
			gmi_rst_n_pi4 {
				nvidia,pins = "gmi_rst_n_pi4";
				nvidia,function = "gmi";
				nvidia,pull = <TEGRA_PIN_PULL_UP>;
				nvidia,tristate = <TEGRA_PIN_ENABLE>;
				nvidia,enable-input = <TEGRA_PIN_DISABLE>;
			};
			gmi_out {
				nvidia,pins = "gmi_wp_n_pc7",
						"gmi_wr_n_pi0",
						"dap2_fs_pa2",
						"dap2_sclk_pa3",
						"dap2_din_pa4",
						"dap2_dout_pa5",
						"spi1_mosi_px4",
						"spi2_mosi_px0",
						"spi2_miso_px1",
						"spi2_sck_px2",
						"spi2_cs0_n_px3",
						"dap4_fs_pp4",
						"dap4_din_pp5",
						"dap4_dout_pp6",
						"dap4_sclk_pp7",
						"pu0",
						"pu1",
						"pu2",
						"pu3",
						"pu4",
						"pu5",
						"pu6",
						"uart2_cts_n_pj5",
						"uart2_rts_n_pj6",
						"uart3_cts_n_pa1",
						"uart3_rts_n_pc0",
						"uart3_txd_pw6",
						"uart3_rxd_pw7";
				nvidia,function = "gmi";
				nvidia,pull = <TEGRA_PIN_PULL_NONE>;
				nvidia,tristate = <TEGRA_PIN_DISABLE>;
				nvidia,enable-input = <TEGRA_PIN_DISABLE>;
			};

			/* DISPLAY pinmux*/
			lcd_pwr1_pc1 {
				nvidia,pins = "lcd_pwr1_pc1";
				nvidia,function = "displaya";
				nvidia,pull = <TEGRA_PIN_PULL_NONE>;
				nvidia,tristate = <TEGRA_PIN_DISABLE>;
				nvidia,enable-input = <TEGRA_PIN_ENABLE>;
			};
			lcd_pwr2_pc6 {
				nvidia,pins = "lcd_pwr2_pc6";
				nvidia,function = "displaya";
				nvidia,pull = <TEGRA_PIN_PULL_NONE>;
				nvidia,tristate = <TEGRA_PIN_DISABLE>;
				nvidia,enable-input = <TEGRA_PIN_ENABLE>;
			};
			lcd_cs0_n_pn4 {
				nvidia,pins = "lcd_cs0_n_pn4";
				nvidia,function = "rsvd4";
				nvidia,pull = <TEGRA_PIN_PULL_NONE>;
				nvidia,tristate = <TEGRA_PIN_DISABLE>;
				nvidia,enable-input = <TEGRA_PIN_ENABLE>;
			};

			/* PEX pinmux */
			pex_l1_prsnt_n_pdd4 {
				nvidia,pins = "pex_l1_prsnt_n_pdd4";
				nvidia,function = "pcie";
				nvidia,pull = <TEGRA_PIN_PULL_NONE>;
				nvidia,tristate = <TEGRA_PIN_ENABLE>;
				nvidia,enable-input = <TEGRA_PIN_ENABLE>;
			};
			pex_l1_rst_n_pdd5 {
				nvidia,pins = "pex_l1_rst_n_pdd5";
				nvidia,function = "pcie";
				nvidia,pull = <TEGRA_PIN_PULL_NONE>;
				nvidia,tristate = <TEGRA_PIN_ENABLE>;
				nvidia,enable-input = <TEGRA_PIN_DISABLE>;
			};
			pex_l1_clkreq_n_pdd6 {
				nvidia,pins = "pex_l1_clkreq_n_pdd6";
				nvidia,function = "pcie";
				nvidia,pull = <TEGRA_PIN_PULL_NONE>;
				nvidia,tristate = <TEGRA_PIN_DISABLE>;
				nvidia,enable-input = <TEGRA_PIN_ENABLE>;
			};
			pex_l2_prsnt_n_pdd7 {
				nvidia,pins = "pex_l2_prsnt_n_pdd7";
				nvidia,function = "pcie";
				nvidia,pull = <TEGRA_PIN_PULL_NONE>;
				nvidia,tristate = <TEGRA_PIN_ENABLE>;
				nvidia,enable-input = <TEGRA_PIN_ENABLE>;
			};
			pex_l2_rst_n_pcc6 {
				nvidia,pins = "pex_l2_rst_n_pcc6";
				nvidia,function = "pcie";
				nvidia,pull = <TEGRA_PIN_PULL_NONE>;
				nvidia,tristate = <TEGRA_PIN_ENABLE>;
				nvidia,enable-input = <TEGRA_PIN_DISABLE>;
			};
			pex_l2_clkreq_n_pcc7 {
				nvidia,pins = "pex_l2_clkreq_n_pcc7";
				nvidia,function = "pcie";
				nvidia,pull = <TEGRA_PIN_PULL_NONE>;
				nvidia,tristate = <TEGRA_PIN_DISABLE>;
				nvidia,enable-input = <TEGRA_PIN_ENABLE>;
			};

			/* CLK1_OUT pinmux*/
			clk1_out_pw4 {
				nvidia,pins = "clk1_out_pw4";
				nvidia,function = "extperiph1";
				nvidia,pull = <TEGRA_PIN_PULL_NONE>;
				nvidia,tristate = <TEGRA_PIN_DISABLE>;
				nvidia,enable-input = <TEGRA_PIN_ENABLE>;
			};

			/* VI pinmux */
			vi_input {
				nvidia,pins = "vi_d2_pl0",
						"vi_d3_pl1",
						"vi_d4_pl2",
						"vi_d5_pl3",
						"vi_d6_pl4",
						"vi_d7_pl5",
						"vi_d8_pl6",
						"vi_d9_pl7";
				nvidia,function = "vi";
				nvidia,pull = <TEGRA_PIN_PULL_NONE>;
				nvidia,tristate = <TEGRA_PIN_DISABLE>;
				nvidia,enable-input = <TEGRA_PIN_ENABLE>;
				nvidia,lock = <TEGRA_PIN_DISABLE>;
				nvidia,io-reset = <TEGRA_PIN_DISABLE>;
			};
			vi_pclk_pt0 {
				nvidia,pins = "vi_pclk_pt0";
				nvidia,function = "vi";
				nvidia,pull = <TEGRA_PIN_PULL_UP>;
				nvidia,tristate = <TEGRA_PIN_ENABLE>;
				nvidia,enable-input = <TEGRA_PIN_ENABLE>;
				nvidia,lock = <TEGRA_PIN_DISABLE>;
				nvidia,io-reset = <TEGRA_PIN_DISABLE>;
			};

			/* GPIO pinmux */
			vi_d0_pt4 {
				nvidia,pins = "vi_d0_pt4";
				nvidia,function = "rsvd2";
				nvidia,pull = <TEGRA_PIN_PULL_NONE>;
				nvidia,tristate = <TEGRA_PIN_DISABLE>;
				nvidia,enable-input = <TEGRA_PIN_ENABLE>;
			};

			clk1_req_pee2 {
				nvidia,pins = "clk1_req_pee2";
				nvidia,function = "rsvd3";
				nvidia,pull = <TEGRA_PIN_PULL_NONE>;
				nvidia,tristate = <TEGRA_PIN_DISABLE>;
				nvidia,enable-input = <TEGRA_PIN_ENABLE>;
			};
			clk2_req_pcc5 {
				nvidia,pins = "clk2_req_pcc5";
				nvidia,function = "rsvd3";
				nvidia,pull = <TEGRA_PIN_PULL_NONE>;
				nvidia,tristate = <TEGRA_PIN_DISABLE>;
				nvidia,enable-input = <TEGRA_PIN_DISABLE>;
			};
			lcd_sck_pz4 {
				nvidia,pins = "lcd_sck_pz4";
				nvidia,function = "spi5";
				nvidia,pull = <TEGRA_PIN_PULL_NONE>;
				nvidia,tristate = <TEGRA_PIN_DISABLE>;
				nvidia,enable-input = <TEGRA_PIN_ENABLE>;
			};
			clk3_out_pee0 {
				nvidia,pins = "clk3_out_pee0";
				nvidia,function = "extperiph3";
				nvidia,pull = <TEGRA_PIN_PULL_NONE>;
				nvidia,tristate = <TEGRA_PIN_DISABLE>;
				nvidia,enable-input = <TEGRA_PIN_ENABLE>;
			};
			hdmi_int_pn7 {
				nvidia,pins = "hdmi_int_pn7";
				nvidia,function = "hdmi";
				nvidia,pull = <TEGRA_PIN_PULL_NONE>;
				nvidia,tristate = <TEGRA_PIN_ENABLE>;
				nvidia,enable-input = <TEGRA_PIN_ENABLE>;
			};
			lcd_dc0_pn6 {
				nvidia,pins = "lcd_dc0_pn6";
				nvidia,function = "rsvd3";
				nvidia,pull = <TEGRA_PIN_PULL_NONE>;
				nvidia,tristate = <TEGRA_PIN_DISABLE>;
				nvidia,enable-input = <TEGRA_PIN_ENABLE>;
			};
			lcd_dc1_pd2 {
				nvidia,pins = "lcd_dc1_pd2";
				nvidia,function = "rsvd3";
				nvidia,pull = <TEGRA_PIN_PULL_NONE>;
				nvidia,tristate = <TEGRA_PIN_DISABLE>;
				nvidia,enable-input = <TEGRA_PIN_ENABLE>;
			};
			lcd_m1_pw1 {
				nvidia,pins = "lcd_m1_pw1";
				nvidia,function = "rsvd3";
				nvidia,pull = <TEGRA_PIN_PULL_NONE>;
				nvidia,tristate = <TEGRA_PIN_DISABLE>;
				nvidia,enable-input = <TEGRA_PIN_ENABLE>;
			};
			lcd_pwr0_pb2 {
				nvidia,pins = "lcd_pwr0_pb2";
				nvidia,function = "spi5";
				nvidia,pull = <TEGRA_PIN_PULL_NONE>;
				nvidia,tristate = <TEGRA_PIN_DISABLE>;
				nvidia,enable-input = <TEGRA_PIN_ENABLE>;
			};
			lcd_sdin_pz2 {
				nvidia,pins = "lcd_sdin_pz2";
				nvidia,function = "rsvd4";
				nvidia,pull = <TEGRA_PIN_PULL_NONE>;
				nvidia,tristate = <TEGRA_PIN_DISABLE>;
				nvidia,enable-input = <TEGRA_PIN_ENABLE>;
			};
			lcd_sdout_pn5 {
				nvidia,pins = "lcd_sdout_pn5";
				nvidia,function = "spi5";
				nvidia,pull = <TEGRA_PIN_PULL_NONE>;
				nvidia,tristate = <TEGRA_PIN_DISABLE>;
				nvidia,enable-input = <TEGRA_PIN_ENABLE>;
			};
			pv0 {
				nvidia,pins = "pv0";
				nvidia,function = "rsvd1";
				nvidia,pull = <TEGRA_PIN_PULL_NONE>;
				nvidia,tristate = <TEGRA_PIN_DISABLE>;
				nvidia,enable-input = <TEGRA_PIN_ENABLE>;
			};
			pv1 {
				nvidia,pins = "pv1";
				nvidia,function = "rsvd1";
				nvidia,pull = <TEGRA_PIN_PULL_NONE>;
				nvidia,tristate = <TEGRA_PIN_DISABLE>;
				nvidia,enable-input = <TEGRA_PIN_ENABLE>;
			};
			pv2 {
				nvidia,pins = "pv2";
				nvidia,function = "rsvd2";
				nvidia,pull = <TEGRA_PIN_PULL_NONE>;
				nvidia,tristate = <TEGRA_PIN_DISABLE>;
				nvidia,enable-input = <TEGRA_PIN_ENABLE>;
			};
			pv3 {
				nvidia,pins = "pv3";
				nvidia,function = "rsvd2";
				nvidia,pull = <TEGRA_PIN_PULL_NONE>;
				nvidia,tristate = <TEGRA_PIN_DISABLE>;
				nvidia,enable-input = <TEGRA_PIN_ENABLE>;
			};
			pex_wake_n_pdd3 {
				nvidia,pins = "pex_wake_n_pdd3";
				nvidia,function = "pcie";
				nvidia,pull = <TEGRA_PIN_PULL_NONE>;
				nvidia,tristate = <TEGRA_PIN_DISABLE>;
				nvidia,enable-input = <TEGRA_PIN_ENABLE>;
			};
			sdmmc3_data {
				nvidia,pins = "sdmmc3_dat4_pd1",
						"sdmmc3_dat5_pd0",
						"sdmmc3_dat6_pd3";
				nvidia,function = "sdmmc3";
				nvidia,pull = <TEGRA_PIN_PULL_NONE>;
				nvidia,tristate = <TEGRA_PIN_DISABLE>;
				nvidia,enable-input = <TEGRA_PIN_ENABLE>;
			};
			sdmmc4_clk_pcc4 {
				nvidia,pins = "sdmmc4_clk_pcc4";
				nvidia,function = "nand";
				nvidia,pull = <TEGRA_PIN_PULL_NONE>;
				nvidia,tristate = <TEGRA_PIN_DISABLE>;
				nvidia,enable-input = <TEGRA_PIN_ENABLE>;
				nvidia,lock = <TEGRA_PIN_DISABLE>;
				nvidia,io-reset = <TEGRA_PIN_DISABLE>;
			};
			spdif_out_pk5 {
				nvidia,pins = "spdif_out_pk5";
				nvidia,function = "rsvd2";
				nvidia,pull = <TEGRA_PIN_PULL_NONE>;
				nvidia,tristate = <TEGRA_PIN_DISABLE>;
				nvidia,enable-input = <TEGRA_PIN_ENABLE>;
			};
			spi1_miso_px7 {
				nvidia,pins = "spi1_miso_px7";
				nvidia,function = "rsvd4";
				nvidia,pull = <TEGRA_PIN_PULL_NONE>;
				nvidia,tristate = <TEGRA_PIN_DISABLE>;
				nvidia,enable-input = <TEGRA_PIN_ENABLE>;
			};
		};

		state_sdmmc1_default: pinmux_sdmmc1_default {
			/* SDMMC1 pinmux in active mode */
			sdmmc1_data {
				nvidia,pins = "sdmmc1_dat0_py7",
						"sdmmc1_dat1_py6",
						"sdmmc1_dat2_py5",
						"sdmmc1_dat3_py4";
				nvidia,function = "sdmmc1";
				nvidia,pull = <TEGRA_PIN_PULL_UP>;
				nvidia,tristate = <TEGRA_PIN_DISABLE>;
				nvidia,enable-input = <TEGRA_PIN_ENABLE>;
			};
			sdmmc1_clk_pz0 {
				nvidia,pins = "sdmmc1_clk_pz0";
				nvidia,function = "sdmmc1";
				nvidia,pull = <TEGRA_PIN_PULL_NONE>;
				nvidia,tristate = <TEGRA_PIN_DISABLE>;
				nvidia,enable-input = <TEGRA_PIN_ENABLE>;
			};
			sdmmc1_cmd_pz1 {
				nvidia,pins = "sdmmc1_cmd_pz1";
				nvidia,function = "sdmmc1";
				nvidia,pull = <TEGRA_PIN_PULL_UP>;
				nvidia,tristate = <TEGRA_PIN_DISABLE>;
				nvidia,enable-input = <TEGRA_PIN_ENABLE>;
			};
		};

		state_sdmmc1_sleep: pinmux_sdmmc1_sleep {
			/* SDMMC1 pinmux in tristate mode */
			sdmmc1_data {
				nvidia,pins = "sdmmc1_dat0_py7",
						"sdmmc1_dat1_py6",
						"sdmmc1_dat2_py5",
						"sdmmc1_dat3_py4";
				nvidia,function = "sdmmc1";
				nvidia,pull = <TEGRA_PIN_PULL_UP>;
				nvidia,tristate = <TEGRA_PIN_ENABLE>;
				nvidia,enable-input = <TEGRA_PIN_ENABLE>;
			};
			sdmmc1_clk_pz0 {
				nvidia,pins = "sdmmc1_clk_pz0";
				nvidia,function = "sdmmc1";
				nvidia,pull = <TEGRA_PIN_PULL_NONE>;
				nvidia,tristate = <TEGRA_PIN_ENABLE>;
				nvidia,enable-input = <TEGRA_PIN_ENABLE>;
			};
			sdmmc1_cmd_pz1 {
				nvidia,pins = "sdmmc1_cmd_pz1";
				nvidia,function = "sdmmc1";
				nvidia,pull = <TEGRA_PIN_PULL_UP>;
				nvidia,tristate = <TEGRA_PIN_ENABLE>;
				nvidia,enable-input = <TEGRA_PIN_ENABLE>;
			};
		};

		state_spi1_default: pinmux_spi1_default {
			/* SPI1 pinmux in active state */
			ulpi_clk_py0 {
				nvidia,pins = "ulpi_clk_py0";
				nvidia,function = "spi1";
				nvidia,pull = <TEGRA_PIN_PULL_NONE>;
				nvidia,tristate = <TEGRA_PIN_DISABLE>;
				nvidia,enable-input = <TEGRA_PIN_ENABLE>;
			};
			ulpi_dir_py1 {
				nvidia,pins = "ulpi_dir_py1";
				nvidia,function = "spi1";
				nvidia,pull = <TEGRA_PIN_PULL_NONE>;
				nvidia,tristate = <TEGRA_PIN_DISABLE>;
				nvidia,enable-input = <TEGRA_PIN_ENABLE>;
			};
			ulpi_nxt_py2 {
				nvidia,pins = "ulpi_nxt_py2";
				nvidia,function = "spi1";
				nvidia,pull = <TEGRA_PIN_PULL_NONE>;
				nvidia,tristate = <TEGRA_PIN_DISABLE>;
				nvidia,enable-input = <TEGRA_PIN_ENABLE>;
			};
			ulpi_stp_py3 {
				nvidia,pins = "ulpi_stp_py3";
				nvidia,function = "spi1";
				nvidia,pull = <TEGRA_PIN_PULL_NONE>;
				nvidia,tristate = <TEGRA_PIN_DISABLE>;
				nvidia,enable-input = <TEGRA_PIN_ENABLE>;
			};
		};

		state_spi1_sleep: pinmux_spi1_sleep {
			/* SPI1 pinmux in sleep state */
			ulpi_clk_py0 {
				nvidia,pins = "ulpi_clk_py0";
				nvidia,function = "spi1";
				nvidia,pull = <TEGRA_PIN_PULL_NONE>;
				nvidia,tristate = <TEGRA_PIN_ENABLE>;
				nvidia,enable-input = <TEGRA_PIN_ENABLE>;
			};
			ulpi_dir_py1 {
				nvidia,pins = "ulpi_dir_py1";
				nvidia,function = "spi1";
				nvidia,pull = <TEGRA_PIN_PULL_NONE>;
				nvidia,tristate = <TEGRA_PIN_ENABLE>;
				nvidia,enable-input = <TEGRA_PIN_ENABLE>;
			};
			ulpi_nxt_py2 {
				nvidia,pins = "ulpi_nxt_py2";
				nvidia,function = "spi1";
				nvidia,pull = <TEGRA_PIN_PULL_NONE>;
				nvidia,tristate = <TEGRA_PIN_ENABLE>;
				nvidia,enable-input = <TEGRA_PIN_ENABLE>;
			};
			ulpi_stp_py3 {
				nvidia,pins = "ulpi_stp_py3";
				nvidia,function = "spi1";
				nvidia,pull = <TEGRA_PIN_PULL_NONE>;
				nvidia,tristate = <TEGRA_PIN_ENABLE>;
				nvidia,enable-input = <TEGRA_PIN_ENABLE>;
			};
		};

		state_dap1_default: pinmux_dap1_default {
			/* DAP1 pinmux (DSP) in active mode */
			dap1_fs_pn0 {
				nvidia,pins = "dap1_fs_pn0";
				nvidia,function = "i2s0";
				nvidia,pull = <TEGRA_PIN_PULL_NONE>;
				nvidia,tristate = <TEGRA_PIN_DISABLE>;
				nvidia,enable-input = <TEGRA_PIN_ENABLE>;
			};
			dap1_din_pn1 {
				nvidia,pins = "dap1_din_pn1";
				nvidia,function = "i2s0";
				nvidia,pull = <TEGRA_PIN_PULL_NONE>;
				nvidia,tristate = <TEGRA_PIN_DISABLE>;
				nvidia,enable-input = <TEGRA_PIN_ENABLE>;
			};
			dap1_dout_pn2 {
				nvidia,pins = "dap1_dout_pn2";
				nvidia,function = "i2s0";
				nvidia,pull = <TEGRA_PIN_PULL_NONE>;
				nvidia,tristate = <TEGRA_PIN_DISABLE>;
				nvidia,enable-input = <TEGRA_PIN_ENABLE>;
			};
			dap1_sclk_pn3 {
				nvidia,pins = "dap1_sclk_pn3";
				nvidia,function = "i2s0";
				nvidia,pull = <TEGRA_PIN_PULL_NONE>;
				nvidia,tristate = <TEGRA_PIN_DISABLE>;
				nvidia,enable-input = <TEGRA_PIN_ENABLE>;
			};
		};

		state_dap1_sleep: pinmux_dap1_sleep {
			/* DAP1 pinmux (DSP) in sleep mode */
			dap1_fs_pn0 {
				nvidia,pins = "dap1_fs_pn0";
				nvidia,function = "i2s0";
				nvidia,pull = <TEGRA_PIN_PULL_NONE>;
				nvidia,tristate = <TEGRA_PIN_ENABLE>;
				nvidia,enable-input = <TEGRA_PIN_ENABLE>;
			};
			dap1_din_pn1 {
				nvidia,pins = "dap1_din_pn1";
				nvidia,function = "i2s0";
				nvidia,pull = <TEGRA_PIN_PULL_NONE>;
				nvidia,tristate = <TEGRA_PIN_ENABLE>;
				nvidia,enable-input = <TEGRA_PIN_ENABLE>;
			};
			dap1_dout_pn2 {
				nvidia,pins = "dap1_dout_pn2";
				nvidia,function = "i2s0";
				nvidia,pull = <TEGRA_PIN_PULL_NONE>;
				nvidia,tristate = <TEGRA_PIN_ENABLE>;
				nvidia,enable-input = <TEGRA_PIN_ENABLE>;
			};
			dap1_sclk_pn3 {
				nvidia,pins = "dap1_sclk_pn3";
				nvidia,function = "i2s0";
				nvidia,pull = <TEGRA_PIN_PULL_NONE>;
				nvidia,tristate = <TEGRA_PIN_ENABLE>;
				nvidia,enable-input = <TEGRA_PIN_ENABLE>;
			};
		};

		state_lcd_default: pinmux_lcd_default {
			/* LCD pinmux in active mode */
			lcd_cs1_n_pw0 {
				nvidia,pins = "lcd_cs1_n_pw0";
				nvidia,function = "displaya";
				nvidia,pull = <TEGRA_PIN_PULL_NONE>;
				nvidia,tristate = <TEGRA_PIN_ENABLE>;
				nvidia,enable-input = <TEGRA_PIN_ENABLE>;
			};
			lcd_inputs {
				nvidia,pins = "lcd_d0_pe0",
						"lcd_d1_pe1",
						"lcd_d2_pe2",
						"lcd_d3_pe3",
						"lcd_d4_pe4",
						"lcd_d5_pe5",
						"lcd_d6_pe6",
						"lcd_d7_pe7",
						"lcd_d8_pf0",
						"lcd_d9_pf1",
						"lcd_d10_pf2",
						"lcd_d11_pf3",
						"lcd_d12_pf4",
						"lcd_d13_pf5",
						"lcd_d14_pf6",
						"lcd_d15_pf7",
						"lcd_d16_pm0",
						"lcd_d17_pm1",
						"lcd_d18_pm2",
						"lcd_d19_pm3",
						"lcd_d20_pm4",
						"lcd_d21_pm5",
						"lcd_d22_pm6",
						"lcd_d23_pm7";
				nvidia,function = "displaya";
				nvidia,pull = <TEGRA_PIN_PULL_NONE>;
				nvidia,tristate = <TEGRA_PIN_DISABLE>;
				nvidia,enable-input = <TEGRA_PIN_ENABLE>;
			};
			lcd_de_pj1 {
				nvidia,pins = "lcd_de_pj1";
				nvidia,function = "displaya";
				nvidia,pull = <TEGRA_PIN_PULL_NONE>;
				nvidia,tristate = <TEGRA_PIN_DISABLE>;
				nvidia,enable-input = <TEGRA_PIN_ENABLE>;
			};
			lcd_hsync_pj3 {
				nvidia,pins = "lcd_hsync_pj3";
				nvidia,function = "displaya";
				nvidia,pull = <TEGRA_PIN_PULL_NONE>;
				nvidia,tristate = <TEGRA_PIN_DISABLE>;
				nvidia,enable-input = <TEGRA_PIN_ENABLE>;
			};
			lcd_pclk_pb3 {
				nvidia,pins = "lcd_pclk_pb3";
				nvidia,function = "displaya";
				nvidia,pull = <TEGRA_PIN_PULL_NONE>;
				nvidia,tristate = <TEGRA_PIN_DISABLE>;
				nvidia,enable-input = <TEGRA_PIN_ENABLE>;
			};
			lcd_vsync_pj4 {
				nvidia,pins = "lcd_vsync_pj4";
				nvidia,function = "displaya";
				nvidia,pull = <TEGRA_PIN_PULL_NONE>;
				nvidia,tristate = <TEGRA_PIN_DISABLE>;
				nvidia,enable-input = <TEGRA_PIN_ENABLE>;
			};
			lcd_wr_n_pz3 {
				nvidia,pins = "lcd_wr_n_pz3";
				nvidia,function = "displaya";
				nvidia,pull = <TEGRA_PIN_PULL_NONE>;
				nvidia,tristate = <TEGRA_PIN_ENABLE>;
				nvidia,enable-input = <TEGRA_PIN_ENABLE>;
			};
		};

		state_lcd_sleep: pinmux_lcd_sleep {
			/* LCD pinmux in sleep mode */
			lcd_cs1_n_pw0 {
				nvidia,pins = "lcd_cs1_n_pw0";
				nvidia,function = "displaya";
				nvidia,pull = <TEGRA_PIN_PULL_NONE>;
				nvidia,tristate = <TEGRA_PIN_ENABLE>;
				nvidia,enable-input = <TEGRA_PIN_ENABLE>;
			};
			lcd_inputs {
				nvidia,pins = "lcd_d0_pe0",
						"lcd_d1_pe1",
						"lcd_d2_pe2",
						"lcd_d3_pe3",
						"lcd_d4_pe4",
						"lcd_d5_pe5",
						"lcd_d6_pe6",
						"lcd_d7_pe7",
						"lcd_d8_pf0",
						"lcd_d9_pf1",
						"lcd_d10_pf2",
						"lcd_d11_pf3",
						"lcd_d12_pf4",
						"lcd_d13_pf5",
						"lcd_d14_pf6",
						"lcd_d15_pf7",
						"lcd_d16_pm0",
						"lcd_d17_pm1",
						"lcd_d18_pm2",
						"lcd_d19_pm3",
						"lcd_d20_pm4",
						"lcd_d21_pm5",
						"lcd_d22_pm6",
						"lcd_d23_pm7";
				nvidia,function = "displaya";
				nvidia,pull = <TEGRA_PIN_PULL_NONE>;
				nvidia,tristate = <TEGRA_PIN_ENABLE>;
				nvidia,enable-input = <TEGRA_PIN_ENABLE>;
			};
			lcd_de_pj1 {
				nvidia,pins = "lcd_de_pj1";
				nvidia,function = "displaya";
				nvidia,pull = <TEGRA_PIN_PULL_NONE>;
				nvidia,tristate = <TEGRA_PIN_ENABLE>;
				nvidia,enable-input = <TEGRA_PIN_ENABLE>;
			};
			lcd_hsync_pj3 {
				nvidia,pins = "lcd_hsync_pj3";
				nvidia,function = "displaya";
				nvidia,pull = <TEGRA_PIN_PULL_NONE>;
				nvidia,tristate = <TEGRA_PIN_ENABLE>;
				nvidia,enable-input = <TEGRA_PIN_ENABLE>;
			};
			lcd_pclk_pb3 {
				nvidia,pins = "lcd_pclk_pb3";
				nvidia,function = "displaya";
				nvidia,pull = <TEGRA_PIN_PULL_NONE>;
				nvidia,tristate = <TEGRA_PIN_ENABLE>;
				nvidia,enable-input = <TEGRA_PIN_ENABLE>;
			};
			lcd_vsync_pj4 {
				nvidia,pins = "lcd_vsync_pj4";
				nvidia,function = "displaya";
				nvidia,pull = <TEGRA_PIN_PULL_NONE>;
				nvidia,tristate = <TEGRA_PIN_ENABLE>;
				nvidia,enable-input = <TEGRA_PIN_ENABLE>;
			};
			lcd_wr_n_pz3 {
				nvidia,pins = "lcd_wr_n_pz3";
				nvidia,function = "displaya";
				nvidia,pull = <TEGRA_PIN_PULL_NONE>;
				nvidia,tristate = <TEGRA_PIN_ENABLE>;
				nvidia,enable-input = <TEGRA_PIN_ENABLE>;
			};
		};

		state_misc_default: pinmux_misc_defaul {
			/* active mode for misc GPIOs */
			ulpi_data1_po2 {
				nvidia,pins = "ulpi_data1_po2";
				nvidia,function = "uarta";
				nvidia,pull = <TEGRA_PIN_PULL_NONE>;
				nvidia,tristate = <TEGRA_PIN_DISABLE>;
				nvidia,enable-input = <TEGRA_PIN_ENABLE>;
			};
			ulpi_data2_po3 {
				nvidia,pins = "ulpi_data2_po3";
				nvidia,function = "uarta";
				nvidia,pull = <TEGRA_PIN_PULL_NONE>;
				nvidia,tristate = <TEGRA_PIN_ENABLE>;
				nvidia,enable-input = <TEGRA_PIN_ENABLE>;
			};
			ulpi_data3_po4 {
				nvidia,pins = "ulpi_data3_po4";
				nvidia,function = "uarta";
				nvidia,pull = <TEGRA_PIN_PULL_NONE>;
				nvidia,tristate = <TEGRA_PIN_ENABLE>;
				nvidia,enable-input = <TEGRA_PIN_DISABLE>;
			};

			/* UART2 pinmux */
			uart2_txd_pc2 {
				nvidia,pins = "uart2_txd_pc2";
				nvidia,function = "uartb";
				nvidia,pull = <TEGRA_PIN_PULL_NONE>;
				nvidia,tristate = <TEGRA_PIN_DISABLE>;
				nvidia,enable-input = <TEGRA_PIN_DISABLE>;
			};
			uart2_rxd_pc3 {
				nvidia,pins = "uart2_rxd_pc3";
				nvidia,function = "uartb";
				nvidia,pull = <TEGRA_PIN_PULL_NONE>;
				nvidia,tristate = <TEGRA_PIN_DISABLE>;
				nvidia,enable-input = <TEGRA_PIN_ENABLE>;
			};

			/* UART4 pinmux */
			gmi_a16_pj7 {
				nvidia,pins = "gmi_a16_pj7";
				nvidia,function = "uartd";
				nvidia,pull = <TEGRA_PIN_PULL_NONE>;
				nvidia,tristate = <TEGRA_PIN_DISABLE>;
				nvidia,enable-input = <TEGRA_PIN_DISABLE>;
			};
			gmi_a17_pb0 {
				nvidia,pins = "gmi_a17_pb0";
				nvidia,function = "uartd";
				nvidia,pull = <TEGRA_PIN_PULL_NONE>;
				nvidia,tristate = <TEGRA_PIN_DISABLE>;
				nvidia,enable-input = <TEGRA_PIN_ENABLE>;
			};
			gmi_a18_pb1 {
				nvidia,pins = "gmi_a18_pb1";
				nvidia,function = "uartd";
				nvidia,pull = <TEGRA_PIN_PULL_NONE>;
				nvidia,tristate = <TEGRA_PIN_DISABLE>;
				nvidia,enable-input = <TEGRA_PIN_ENABLE>;
			};
			gmi_a19_pk7 {
				nvidia,pins = "gmi_a19_pk7";
				nvidia,function = "uartd";
				nvidia,pull = <TEGRA_PIN_PULL_NONE>;
				nvidia,tristate = <TEGRA_PIN_DISABLE>;
				nvidia,enable-input = <TEGRA_PIN_DISABLE>;
			};

			/* UART5 pinmux */
			sdmmc4_dat0_paa0 {
				nvidia,pins = "sdmmc4_dat0_paa0";
				nvidia,function = "uarte";
				nvidia,pull = <TEGRA_PIN_PULL_NONE>;
				nvidia,tristate = <TEGRA_PIN_DISABLE>;
				nvidia,enable-input = <TEGRA_PIN_DISABLE>;
				nvidia,lock = <TEGRA_PIN_DISABLE>;
				nvidia,iio-reset = <TEGRA_PIN_DISABLE>;
			};
			sdmmc4_dat1_paa1 {
				nvidia,pins = "sdmmc4_dat1_paa1";
				nvidia,function = "uarte";
				nvidia,pull = <TEGRA_PIN_PULL_NONE>;
				nvidia,tristate = <TEGRA_PIN_DISABLE>;
				nvidia,enable-input = <TEGRA_PIN_ENABLE>;
				nvidia,lock = <TEGRA_PIN_DISABLE>;
				nvidia,iio-reset = <TEGRA_PIN_DISABLE>;
			};
			sdmmc4_dat2_paa2 {
				nvidia,pins = "sdmmc4_dat2_paa2";
				nvidia,function = "uarte";
				nvidia,pull = <TEGRA_PIN_PULL_NONE>;
				nvidia,tristate = <TEGRA_PIN_DISABLE>;
				nvidia,enable-input = <TEGRA_PIN_ENABLE>;
				nvidia,lock = <TEGRA_PIN_DISABLE>;
				nvidia,iio-reset = <TEGRA_PIN_DISABLE>;
			};
			sdmmc4_dat3_paa03 {
				nvidia,pins = "sdmmc4_dat3_paa3";
				nvidia,function = "uarte";
				nvidia,pull = <TEGRA_PIN_PULL_NONE>;
				nvidia,tristate = <TEGRA_PIN_DISABLE>;
				nvidia,enable-input = <TEGRA_PIN_DISABLE>;
				nvidia,lock = <TEGRA_PIN_DISABLE>;
				nvidia,iio-reset = <TEGRA_PIN_DISABLE>;
			};

			sdmmc3_dat0_pb7 {
				nvidia,pins = "sdmmc3_dat0_pb7";
				nvidia,function = "spi3";
				nvidia,pull = <TEGRA_PIN_PULL_NONE>;
				nvidia,tristate = <TEGRA_PIN_DISABLE>;
				nvidia,enable-input = <TEGRA_PIN_ENABLE>;
			};

			sdmmc3_dat1_pb6 {
				nvidia,pins = "sdmmc3_dat1_pb6";
				nvidia,function = "spi3";
				nvidia,pull = <TEGRA_PIN_PULL_NONE>;
				nvidia,tristate = <TEGRA_PIN_DISABLE>;
				nvidia,enable-input = <TEGRA_PIN_ENABLE>;
			};

			sdmmc3_dat2_pb5 {
				nvidia,pins = "sdmmc3_dat2_pb5";
				nvidia,function = "rsvd1";
				nvidia,pull = <TEGRA_PIN_PULL_NONE>;
				nvidia,tristate = <TEGRA_PIN_DISABLE>;
				nvidia,enable-input = <TEGRA_PIN_ENABLE>;
			};
			/* XXX - handle rest of sdmmc3_datX? */
			/* XXX - should all be sdmmc3 function? */
		};
		state_misc_sleep: pinmux_misc_sleep {
			/* sleep mode for misc GPIOs */
			ulpi_data1_po2 {
				nvidia,pins = "ulpi_data1_po2";
				nvidia,function = "uarta";
				nvidia,pull = <TEGRA_PIN_PULL_NONE>;
				nvidia,tristate = <TEGRA_PIN_ENABLE>;
				nvidia,enable-input = <TEGRA_PIN_ENABLE>;
			};
			ulpi_data2_po3 {
				nvidia,pins = "ulpi_data2_po3";
				nvidia,function = "uarta";
				nvidia,pull = <TEGRA_PIN_PULL_NONE>;
				nvidia,tristate = <TEGRA_PIN_ENABLE>;
				nvidia,enable-input = <TEGRA_PIN_ENABLE>;
			};
			ulpi_data3_po4 {
				nvidia,pins = "ulpi_data3_po4";
				nvidia,function = "uarta";
				nvidia,pull = <TEGRA_PIN_PULL_NONE>;
				nvidia,tristate = <TEGRA_PIN_ENABLE>;
				nvidia,enable-input = <TEGRA_PIN_DISABLE>;
			};

			/* UART2 pinmux */
			uart2_txd_pc2 {
				nvidia,pins = "uart2_txd_pc2";
				nvidia,function = "uartb";
				nvidia,pull = <TEGRA_PIN_PULL_NONE>;
				nvidia,tristate = <TEGRA_PIN_ENABLE>;
				nvidia,enable-input = <TEGRA_PIN_DISABLE>;
			};
			uart2_rxd_pc3 {
				nvidia,pins = "uart2_rxd_pc3";
				nvidia,function = "uartb";
				nvidia,pull = <TEGRA_PIN_PULL_NONE>;
				nvidia,tristate = <TEGRA_PIN_ENABLE>;
				nvidia,enable-input = <TEGRA_PIN_ENABLE>;
			};

			/* UART4 pinmux */
			gmi_a16_pj7 {
				nvidia,pins = "gmi_a16_pj7";
				nvidia,function = "uartd";
				nvidia,pull = <TEGRA_PIN_PULL_NONE>;
				nvidia,tristate = <TEGRA_PIN_ENABLE>;
				nvidia,enable-input = <TEGRA_PIN_DISABLE>;
			};
			gmi_a17_pb0 {
				nvidia,pins = "gmi_a17_pb0";
				nvidia,function = "uartd";
				nvidia,pull = <TEGRA_PIN_PULL_NONE>;
				nvidia,tristate = <TEGRA_PIN_ENABLE>;
				nvidia,enable-input = <TEGRA_PIN_ENABLE>;
			};
			gmi_a18_pb1 {
				nvidia,pins = "gmi_a18_pb1";
				nvidia,function = "uartd";
				nvidia,pull = <TEGRA_PIN_PULL_NONE>;
				nvidia,tristate = <TEGRA_PIN_ENABLE>;
				nvidia,enable-input = <TEGRA_PIN_ENABLE>;
			};
			gmi_a19_pk7 {
				nvidia,pins = "gmi_a19_pk7";
				nvidia,function = "uartd";
				nvidia,pull = <TEGRA_PIN_PULL_NONE>;
				nvidia,tristate = <TEGRA_PIN_ENABLE>;
				nvidia,enable-input = <TEGRA_PIN_DISABLE>;
			};

			/* UART5 pinmux */
			sdmmc4_dat0_paa0 {
				nvidia,pins = "sdmmc4_dat0_paa0";
				nvidia,function = "uarte";
				nvidia,pull = <TEGRA_PIN_PULL_NONE>;
				nvidia,tristate = <TEGRA_PIN_ENABLE>;
				nvidia,enable-input = <TEGRA_PIN_DISABLE>;
				nvidia,lock = <TEGRA_PIN_DISABLE>;
				nvidia,iio-reset = <TEGRA_PIN_DISABLE>;
			};
			sdmmc4_dat1_paa1 {
				nvidia,pins = "sdmmc4_dat1_paa1";
				nvidia,function = "uarte";
				nvidia,pull = <TEGRA_PIN_PULL_NONE>;
				nvidia,tristate = <TEGRA_PIN_ENABLE>;
				nvidia,enable-input = <TEGRA_PIN_ENABLE>;
				nvidia,lock = <TEGRA_PIN_DISABLE>;
				nvidia,iio-reset = <TEGRA_PIN_DISABLE>;
			};
			sdmmc4_dat2_paa2 {
				nvidia,pins = "sdmmc4_dat2_paa2";
				nvidia,function = "uarte";
				nvidia,pull = <TEGRA_PIN_PULL_NONE>;
				nvidia,tristate = <TEGRA_PIN_ENABLE>;
				nvidia,enable-input = <TEGRA_PIN_ENABLE>;
				nvidia,lock = <TEGRA_PIN_DISABLE>;
				nvidia,iio-reset = <TEGRA_PIN_DISABLE>;
			};
			sdmmc4_dat3_paa03 {
				nvidia,pins = "sdmmc4_dat3_paa3";
				nvidia,function = "uarte";
				nvidia,pull = <TEGRA_PIN_PULL_NONE>;
				nvidia,tristate = <TEGRA_PIN_ENABLE>;
				nvidia,enable-input = <TEGRA_PIN_DISABLE>;
				nvidia,lock = <TEGRA_PIN_DISABLE>;
				nvidia,iio-reset = <TEGRA_PIN_DISABLE>;
			};

			sdmmc3_dat0_pb7 {
				nvidia,pins = "sdmmc3_dat0_pb7";
				nvidia,function = "spi3";
				nvidia,pull = <TEGRA_PIN_PULL_NONE>;
				nvidia,tristate = <TEGRA_PIN_ENABLE>;
				nvidia,enable-input = <TEGRA_PIN_ENABLE>;
			};

			sdmmc3_dat1_pb6 {
				nvidia,pins = "sdmmc3_dat1_pb6";
				nvidia,function = "spi3";
				nvidia,pull = <TEGRA_PIN_PULL_NONE>;
				nvidia,tristate = <TEGRA_PIN_ENABLE>;
				nvidia,enable-input = <TEGRA_PIN_ENABLE>;
			};

			sdmmc3_dat2_pb5 {
				nvidia,pins = "sdmmc3_dat2_pb5";
				nvidia,function = "rsvd1";
				nvidia,pull = <TEGRA_PIN_PULL_NONE>;
				nvidia,tristate = <TEGRA_PIN_ENABLE>;
				nvidia,enable-input = <TEGRA_PIN_ENABLE>;
			};
			/* XXX - handle rest of sdmmc3_datX? */
			/* XXX - should all be sdmmc3 function? */
		};
	};

	/* i2c1 and i2c2 are exported from module */
	i2c0: i2c@7000c000 {
		status = "okay";
		clock-frequency = <100000>;
	};

	i2c1: i2c@7000c400 {
		status = "okay";
		clock-frequency = <100000>;
	};

	i2c3: i2c@7000c700 {
		status = "okay";
		clock-frequency = <100000>;
	};

	i2c4: i2c@7000d000 {
		status = "okay";
		clock-frequency = <100000>;

#ifdef USE_PMIC
		pmic: tps65911@2d {
			compatible = "ti,tps65911";
			reg = <0x2d>;

			ti,system-power-controller;

			#gpio-cells = <2>;
			gpio-controller;

			vcc1-supply = <&vdd_5v_in>;
			vcc2-supply = <&vdd_5v_in>;
			vcc3-supply = <&vdd_3v3>;
			vcc4-supply = <&vdd_5v_in>;
			vcc5-supply = <&vdd_5v_in>;
			vcc6-supply = <&vdd_1v8>;
			vcc7-supply = <&vdd_5v_in>;
			vccio-supply = <&vdd_io_sys>;

			regulators {
				#address-cells = <1>;
				#size-cells = <0>;

				vdd_pex: vdd1 {
					regulator-name = "vdd_pex_1v05";
					regulator-min-microvolt = <1050000>;
					regulator-max-microvolt = <1050000>;
				};

				vdd_mem: vdd2 {
					regulator-name = "vdd_mem_1v5";
					regulator-min-microvolt = <1500000>;
					regulator-max-microvolt = <1500000>;
					regulator-always-on;
				};

				vdd_1v8: vio {
					regulator-name = "vdd_1v8";
					regulator-min-microvolt = <1800000>;
					regulator-max-microvolt = <1800000>;
					regulator-always-on;
				};

				vdd_pex_pll: ldo1 {
					regulator-name = "vdd_pex_pll_1v05";
					regulator-min-microvolt = <1050000>;
					regulator-max-microvolt = <1050000>;
				};

				vdd_1v2: ldo2 {
					regulator-name = "vdd_1v2";
					regulator-min-microvolt = <1200000>;
					regulator-max-microvolt = <1200000>;
					regulator-always-on;
				};

				vdd_io_sys: ldo3 {
					regulator-name = "vdd_io_sys_1v8";
					regulator-min-microvolt = <1800000>;
					regulator-max-microvolt = <1800000>;
					regulator-always-on;
				};

				vdd_rtc: ldo4 {
					regulator-name = "vdd_rtc_1v2";
					regulator-min-microvolt = <1200000>;
					regulator-max-microvolt = <1200000>;
					regulator-always-on;
				};


				vdd_ddr_hs: ldo5 {
					regulator-name = "vdd_ddr_hs";
					regulator-min-microvolt = <1000000>;
					regulator-max-microvolt = <1000000>;
					regulator-always-on;
				};

				vdd_pll: ldo6 {
					regulator-name = "vdd_pll";
					regulator-min-microvolt = <1800000>;
					regulator-max-microvolt = <1800000>;
					regulator-always-on;
				};

				/* note, schematics claim 2.85V but LDO7 only odes
				 * adjustments in 0.1V steps, so use 2.9V instead */
				vdd_ddr_rx: ldo7 {
					regulator-name = "vdd_ddr_rx";
					regulator-min-microvolt = <2900000>;
					regulator-max-microvolt = <2900000>;
					regulator-always-on;
				};

				vdd_fuse: ldo8 {
					regulator-name = "vdd_fuse";
					regulator-min-microvolt = <3300000>;
					regulator-max-microvolt = <3300000>;
					regulator-always-on;
				};
			};
		};
#endif /* USE_PMIC */
	};

	ahub@70080000 {
		dap1: i2s@70080300 {
			status = "okay";
			nvidia,audio-sync-clk;
		};
	};

	sound {
		compatible = "nvidia,tegra-audio-tesla-cid";
		nvidia,model = "tegra-generic";
		nvidia,i2s-controller = <&dap1>;
		clocks = <&tegra_car TEGRA30_CLK_PLL_A>,
			 <&tegra_car TEGRA30_CLK_PLL_A_OUT0>,
			 <&tegra_car TEGRA30_CLK_EXTERN1>,
			 <&tegra_car TEGRA30_CLK_I2S0_SYNC>;
		clock-names = "pll_a", "pll_a_out0", "mclk", "i2s_sync";
	};

	avp {
		compatible = "nvidia,tegra30-avp";
		interrupts = <GIC_SPI 4 IRQ_TYPE_LEVEL_HIGH>,
			     <GIC_SPI 5 IRQ_TYPE_LEVEL_HIGH>,
			     <GIC_SPI 6 IRQ_TYPE_LEVEL_HIGH>,
			     <GIC_SPI 7 IRQ_TYPE_LEVEL_HIGH>;
		clocks = <&tegra_car TEGRA30_CLK_VDE>,
		         <&tegra_car TEGRA30_CLK_BSEV>;
		clock-names = "vde", "bsev";
		resets = <&tegra_car 1>, <&tegra_car 61>, <&tegra_car 63>;
		reset-names = "cop", "vde", "bsev";
	};

	clocks {
		compatible = "simple-bus";
		#address-cells = <1>;
		#size-cells = <0>;

		clk32k_in: clock@0 {
			compatible = "fixed-clock";
			reg=<0>;
			#clock-cells = <0>;
			clock-frequency = <32768>;
		};
	};

	gpios {
		compatible = "gpios,gpio-of";

		t4 {
			gpios = <&gpio TEGRA_GPIO(T, 4) GPIO_ACTIVE_HIGH >;
			gpio,set-out = <1>;
		};
		w4 {
			gpios = <&gpio TEGRA_GPIO(W, 4) GPIO_ACTIVE_HIGH >;
			gpio,set-out = <1>;
		};
		local_vbus_en {
			gpios = <&gpio TEGRA_GPIO(EE, 2) GPIO_ACTIVE_HIGH >;
			gpio,set-out = <1>;
		};
		usb_hub_reset {
			gpios = <&gpio TEGRA_GPIO(Z, 4) GPIO_ACTIVE_HIGH >;
			gpio,set-out = <0>;
		};
		d2 {
			gpios = <&gpio TEGRA_GPIO(D, 2) GPIO_ACTIVE_HIGH>;
			gpio,set-out = <1>;
		};
		mnand_reset {
			gpios = <&gpio TEGRA_GPIO(D, 1) GPIO_ACTIVE_HIGH>;
			gpio,set-out = <0>;
		};
		dsp_reset {
			gpios = <&gpio TEGRA_GPIO(D, 0) GPIO_ACTIVE_HIGH>;
			gpio,set-out = <0>;
		};
		therm_alert {
			gpios = <&gpio TEGRA_GPIO(W, 3) GPIO_ACTIVE_HIGH>;
			gpio,set-input;
		};
		user1 {
			gpios = <&gpio TEGRA_GPIO(K, 5) GPIO_ACTIVE_HIGH>;
			gpio,set-out = <1>;
		};
		parrot_boots {
			gpios = <&gpio TEGRA_GPIO(X, 5) GPIO_ACTIVE_HIGH>;
			gpio,set-out = <0>;
		};
		auth_reset {
			gpios = <&gpio TEGRA_GPIO(X, 6) GPIO_ACTIVE_HIGH>;
			gpio,set-out = <0>;
		};
		touch_reset {
			gpios = <&gpio TEGRA_GPIO(C, 6) GPIO_ACTIVE_HIGH>;
			gpio,set-out = <0>;
		};
		parrot_reset {
			gpios = <&gpio TEGRA_GPIO(V, 3) GPIO_ACTIVE_HIGH>;
			gpio,set-out = <0>;
		};
		media_sd1_pwr {
			gpios = <&gpio TEGRA_GPIO(V, 6) GPIO_ACTIVE_HIGH>;
			gpio,set-out = <0>;
		};
		dsp_ctl_sync {
			gpios = <&gpio TEGRA_GPIO(C, 1) GPIO_ACTIVE_HIGH>;
			gpio,set-input;
		};
		gps_reset {
			gpios = <&gpio TEGRA_GPIO(DD, 3) GPIO_ACTIVE_HIGH>;
			gpio,set-input;
		};
		eth_sw_en {
			gpios = <&gpio TEGRA_GPIO(EE, 0) GPIO_ACTIVE_HIGH>;
			gpio,set-out = <1>;
		};
		sd_pending {
			/* technically, active low, but user-space compat */
			gpios = <&gpio TEGRA_GPIO(X, 7) GPIO_ACTIVE_HIGH>;
			gpio,set-input;
		};
		gps_reset_d {
			gpios = <&gpio TEGRA_GPIO(V, 7) GPIO_ACTIVE_HIGH>;
			gpio,set-input;
		};
		media_sleep_shdwn {
			gpios = <&gpio TEGRA_GPIO(B, 6) GPIO_ACTIVE_HIGH>;
			gpio,set-out = <0>;
		};
		gtw_wake {
			gpios = <&gpio TEGRA_GPIO(B, 7) GPIO_ACTIVE_HIGH>;
			gpio,set-out = <0>;
		};
		lte_vbus_en {
			gpios = <&gpio TEGRA_GPIO(CC, 5) GPIO_ACTIVE_HIGH >;
			gpio,set-out = <1>;
		};
		dsp_out {
			gpios = <&gpio TEGRA_GPIO(Y, 3) GPIO_ACTIVE_HIGH >;
			gpio,set-out = <1>;
		};
		b5 {
			gpios = <&gpio TEGRA_GPIO(B, 5) GPIO_ACTIVE_HIGH >;
			gpio,set-out = <1>;
		};
	};

	hda@70030000 {
		status = "okay";
	};

	/* override the host1x nodes for our comaptibility layer */
	host1x@50000000 {
		/* not using carveouts at the moment */

		/* override ranges to allow syncpt driver to bind */
		ranges = <0x50000000 0x50000000 0x08000000>;

		syncptirq@50003000 {
			compatible = "nvidia,tegra30-syncpt-irq";
			reg = <0x50003000 0x100>;
			interrupt-parent = <&lic>;
			interrupts = <GIC_SPI 65 IRQ_TYPE_LEVEL_HIGH>;
			interrupt-controller;
			#interrupt-cells = <1>;
		};

		dsi@54300000 {
			status = "okay";
		};

		dsi@54400000 {
			status = "okay";
			nvidia,head = <1>;
		};
	};

	nor@70009000 {
		status = "okay";
		ranges = <0 0 0x48000000 0x8000000>;
		nvidia,cs-timing = <0x40400273 0x00030302>;

		/* Cypress S29GL512 NOR 64 MiB */
		flash@0,0 {
			compatible = "amd,s29gl512n", "cfi-flash";
			reg = <0 0 0x8000000>;
			linux,mtd-name = "tegra-nor";
			bank-width = <2>;
			device-width = <2>;
			#address-cells = <1>;
			#size-cells = <1>;
		};
	};

	spi0: spi@7000d400 {
		status = "okay";

		spidev@0 {
			compatible = "tesla,userspi";
			reg = <0>;
			spi-max-frequency = <18000000>;
		};
	};

	spi2: spi@7000d800 {
		status = "okay";

		spidev@1 {
			compatible = "tesla,userspi";
			reg = <0>;
			spi-max-frequency = <18000000>;
		};
	};

	/* fixed supply reguators */
	vdd_5v_in: regulator@100 {
		compatible = "regulator-fixed";
		regulator-name = "vdd_5v_in";
		regulator-min-microvolt = <5000000>;
		regulator-max-microvolt = <5000000>;
		regulator-always-on;
	};

	vdd_3v3: regulator@101 {
		compatible = "regulator-fixed";
		regulator-name = "vdd_3v3";
		regulator-min-microvolt = <3300000>;
		regulator-max-microvolt = <3300000>;
		regulator-always-on;
	};

#ifndef USE_PMIC
	/* if we're not using the pmic, add fixed regulators */
	vdd_io_sys: regulator@007 {
		compatible = "regulator-fixed";
		regulator-name = "vdd_1v8";
		regulator-min-microvolt = <1800000>;
		regulator-max-microvolt = <1800000>;
		regulator-always-on;
	};
#endif

#ifdef USING_PMIC
	/* vdd_cpu controlled by TPS659119 gpio1 */
	vdd_cpu: regulator@102 {
		compatible = "regulator-gpio";
		regulator-name = "vdd_cpu";
		regulator-min-microvolt = <850000>;
		regulator-max-microvolt = <1010000>;
		regulator-always-on;
		gpios = <&pmic 1>;
		/* note, we trust the schematics on these values */
		states = < 850000 0
			   1010000 1>;
	};
#else
	/* vdd_cpu controlled by TPS659119 gpio1 */
	vdd_cpu: regulator@102 {
		compatible = "regulator-fixed";
		regulator-name = "vdd_cpu";
		regulator-min-microvolt = <1010000>;
		regulator-max-microvolt = <1010000>;
		regulator-always-on;
	};
#endif

	vdd_1v8_media: regulator@103 {
		compatible = "regulator-fixed";
		regulator-name = "vdd_1v8_media";
		regulator-min-microvolt = <1800000>;
		regulator-max-microvolt = <1800000>;
		regulator-always-on;
	};

	rtc@7000e000 {
		/* rtc currently does not work, so disable */
		status = "disabled";
	};

	/* SD-SDMMC1 */
	sdhci0: sdhci@78000000 {
		status = "okay";
		cd-gpio = <&gpio TEGRA_GPIO(V,2) GPIO_ACTIVE_LOW>;
		bus-width = <4>;
		vmmc-supply = <&vdd_3v3>;
		vqmmc-supply = <&vdd_3v3>;

		pinctrl-names = "default", "sleep";
		pinctrl-0 = <&state_sdmmc1_default>;
		pinctrl-1 = <&state_sdmmc1_sleep>;
	};

	/* KBC-SDMMC2 */
	sdhci1: sdhci@78000200 {
		status = "okay";
		bus-width = <8>;
		vmmc-supply = <&vdd_3v3>;
		vqmmc-supply = <&vdd_1v8_media>;
	};

	/* eMMC-SDMMC4 */
	sdhci2: sdhci@78000600 {
		status = "okay";
		bus-width = <8>;
		non-removable;
		vmmc-supply = <&vdd_3v3>;
		vqmmc-supply = <&vdd_3v3>;

		#address-cells = <1>;
		#size-cells = <0>;
		mmccard0: mmccard@0 {
			reg = <0>;
			compatible = "mmc-card";
		};
	};

	/* debug serial port (UARTA), no flow control */
	serial@70006000 {
		status = "okay";
	};

	/* exported but not used (keep for existing kernel compat) */
	serial@70006040 {
		compatible = "nvidia,tegra30-hsuart", "nvidia,tegra20-hsuart";
		status = "okay";
	};

	/* uart3 is used */
	serial@70006300 {
		compatible = "nvidia,tegra30-hsuart", "nvidia,tegra20-hsuart";
		status = "okay";
	};

	/* exported but not used (keep for existing kernel compat) */
	serial@70006400 {
		compatible = "nvidia,tegra30-hsuart", "nvidia,tegra20-hsuart";
		status = "okay";
	};

	/* all three usb ports available, usb0 is debug
	 * usb1 is connected to onboard usb hub
	 * usb2 is ethernet device for comms
	 */
	usb@7d000000 {
		status = "okay";
	};

	phy1: usb-phy@7d000000 {
		vbus-supply = <&vdd_3v3>;	/* todo - check this */
		status = "okay";
		nvidia,xcvr-setup-use-fuses;
		nvidia,xcvr-fuse-6bit-setup;
		nvidia,xcvr-setup-offset = <6>;
		nvidia,hssync-start-delay = <0>;
		nvidia,xcvr-setup = <52>;
		nvidia,xcvr-lsfslew = <2>;
		nvidia,xcvr-lsrslew = <2>;
		nvidia,xcvr-hsslew = <8>;
	};

	usb@7d004000 {
		status = "okay";
	};

	phy2: usb-phy@7d004000 {
		vbus-supply = <&vdd_3v3>;
		status = "okay";
		nvidia,xcvr-setup-use-fuses;
		nvidia,xcvr-fuse-6bit-setup;
		nvidia,xcvr-setup-offset = <6>;
		nvidia,hssync-start-delay = <0>;
		nvidia,xcvr-setup = <52>;
		nvidia,xcvr-lsfslew = <2>;
		nvidia,xcvr-lsrslew = <2>;
		nvidia,xcvr-hsslew = <8>;
	};

	usb@7d008000 {
		status = "okay";
	};

	phy3: usb-phy@7d008000 {
		vbus-supply = <&vdd_3v3>;
		status = "okay";
		nvidia,xcvr-setup-use-fuses;
		nvidia,xcvr-fuse-6bit-setup;
		nvidia,xcvr-setup-offset = <6>;
		nvidia,hssync-start-delay = <0>;
		nvidia,xcvr-setup = <52>;
		nvidia,xcvr-lsfslew = <2>;
		nvidia,xcvr-lsrslew = <2>;
		nvidia,xcvr-hsslew = <8>;
	};
};
